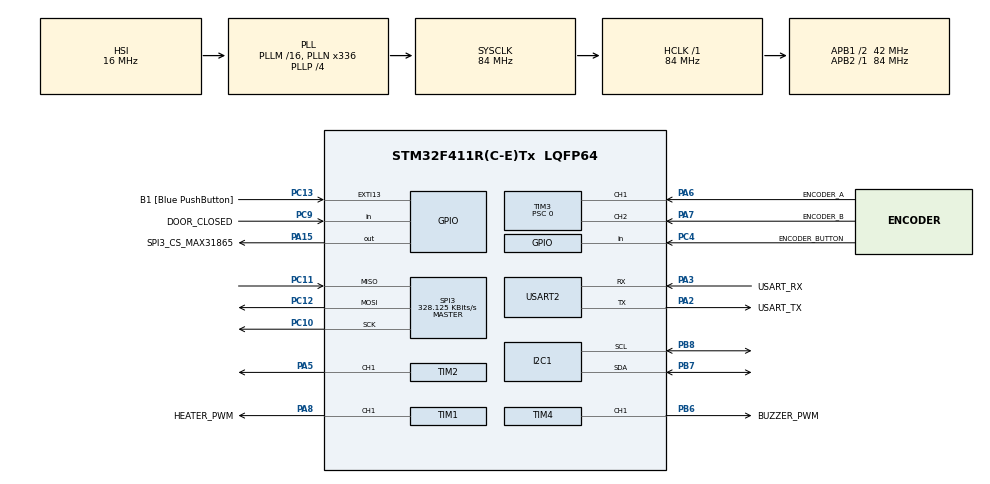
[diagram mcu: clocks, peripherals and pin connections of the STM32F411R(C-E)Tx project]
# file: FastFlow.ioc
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I2C1.I2C_Mode=I2C_Standard
Mcu.Family=STM32F4
Mcu.Name=STM32F411R(C-E)Tx
Mcu.Package=LQFP64
NVIC.PriorityGroup=NVIC_PRIORITYGROUP_0
PA13.GPIO_Label=TMS
PA13.Mode=Serial_Wire
PA13.Signal=SYS_JTMS-SWDIO
PA14.GPIO_Label=TCK
PA14.Mode=Serial_Wire
PA14.Signal=SYS_JTCK-SWCLK
PA15.GPIO_Label=SPI3_CS_MAX31865
PA15.Signal=GPIO_Output
PA2.GPIO_Label=USART_TX
PA2.Mode=Asynchronous
PA2.Signal=USART2_TX
PA3.GPIO_Label=USART_RX
PA3.Mode=Asynchronous
PA3.Signal=USART2_RX
PA5.Signal=S_TIM2_CH1_ETR
PA6.GPIO_Label=ENCODER_A
PA6.Signal=S_TIM3_CH1
PA7.GPIO_Label=ENCODER_B
PA7.Signal=S_TIM3_CH2
PA8.GPIO_Label=HEATER_PWM
PA8.Signal=S_TIM1_CH1
PB3.GPIO_Label=SWO
PB3.Signal=SYS_JTDO-SWO
PB6.GPIO_Label=BUZZER_PWM
PB6.Signal=S_TIM4_CH1
PB7.Mode=I2C
PB7.Signal=I2C1_SDA
PB8.Mode=I2C
PB8.Signal=I2C1_SCL
PC10.Mode=Full_Duplex_Master
PC10.Signal=SPI3_SCK
PC11.Mode=Full_Duplex_Master
PC11.Signal=SPI3_MISO
PC12.Mode=Full_Duplex_Master
PC12.Signal=SPI3_MOSI
PC13-ANTI_TAMP.GPIO_Label=B1 [Blue PushButton]
PC13-ANTI_TAMP.GPIO_ModeDefaultEXTI=GPIO_MODE_IT_FALLING
PC13-ANTI_TAMP.Signal=GPXTI13
PC14-OSC32_IN.Mode=LSE-External-Oscillator
PC14-OSC32_IN.Signal=RCC_OSC32_IN
PC15-OSC32_OUT.Mode=LSE-External-Oscillator
PC15-OSC32_OUT.Signal=RCC_OSC32_OUT
PC4.GPIO_Label=ENCODER_BUTTON
PC4.Signal=GPIO_Input
PC9.GPIO_Label=DOOR_CLOSED
PC9.Signal=GPIO_Input
PH0\ -\ OSC_IN.Mode=HSE-External-Clock-Source
PH0\ -\ OSC_IN.Signal=RCC_OSC_IN
PH1\ -\ OSC_OUT.Mode=HSE-External-Clock-Source
PH1\ -\ OSC_OUT.Signal=RCC_OSC_OUT
ProjectManager.HeapSize=0x200
ProjectManager.StackSize=0x400
ProjectManager.TargetToolchain=STM32CubeIDE
RCC.48MHZClocksFreq_Value=84000000
RCC.AHBFreq_Value=84000000
RCC.APB1CLKDivider=RCC_HCLK_DIV2
RCC.APB1Freq_Value=42000000
RCC.APB1TimFreq_Value=84000000
RCC.APB2Freq_Value=84000000
RCC.APB2TimFreq_Value=84000000
RCC.CortexFreq_Value=84000000
RCC.FLatency-AdvancedSettings=FLASH_LATENCY_2
RCC.HCLKFreq_Value=84000000
RCC.HSE_VALUE=8000000
RCC.HSI_VALUE=16000000
RCC.PLLN=336
RCC.PLLP=RCC_PLLP_DIV4
RCC.SYSCLKFreq_VALUE=84000000
RCC.SYSCLKSource=RCC_SYSCLKSOURCE_PLLCLK
RCC.VCOOutputFreq_Value=336000000
SH.S_TIM1_CH1.0=TIM1_CH1,Output Compare1 CH1
SH.S_TIM2_CH1_ETR.0=TIM2_CH1,PWM Generation1 CH1
SH.S_TIM3_CH1.0=TIM3_CH1,Encoder_Interface
SH.S_TIM3_CH2.0=TIM3_CH2,Encoder_Interface
SH.S_TIM4_CH1.0=TIM4_CH1,Output Compare1 CH1
SPI3.BaudRatePrescaler=SPI_BAUDRATEPRESCALER_128
SPI3.CLKPhase=SPI_PHASE_1EDGE
SPI3.CalculateBaudRate=328.125 KBits/s
SPI3.Direction=SPI_DIRECTION_2LINES
SPI3.Mode=SPI_MODE_MASTER
SPI3.VirtualType=VM_MASTER
TIM1.Channel-Output\ Compare1\ CH1=TIM_CHANNEL_1
TIM2.AutoReloadPreload=TIM_AUTORELOAD_PRELOAD_ENABLE
TIM2.Channel-PWM\ Generation1\ CH1=TIM_CHANNEL_1
TIM2.ClockDivision=TIM_CLOCKDIVISION_DIV1
TIM2.Period=0xFFFF
TIM2.Prescaler=0x0A04
TIM2.Pulse-PWM\ Generation1\ CH1=0x0FFF
TIM3.EncoderMode=TIM_ENCODERMODE_TI12
TIM3.IC1Filter=15
TIM3.IC1Prescaler=TIM_ICPSC_DIV1
TIM3.IC2Filter=15
TIM3.IC2Prescaler=TIM_ICPSC_DIV1
TIM3.Prescaler=0
TIM4.Channel-Output\ Compare1\ CH1=TIM_CHANNEL_1
TIM4.ClockDivision=TIM_CLOCKDIVISION_DIV4
TIM4.Period=0xFFFF
TIM4.Prescaler=20000
TIM4.Pulse-Output\ Compare1\ CH1=0x7FFF
USART2.VirtualMode=VM_ASYNC
VP_TIM2_VS_ClockSourceINT.Mode=Internal
VP_TIM4_VS_ClockSourceINT.Mode=Internal
board=NUCLEO-F411RE

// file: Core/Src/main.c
/* USER CODE BEGIN Header */
/**
  ******************************************************************************
  * @file           : main.c
  * @brief          : Main program body
  ******************************************************************************
  * @attention
  *
  * Copyright (c) 2024 STMicroelectronics.
  * All rights reserved.
  *
  * This software is licensed under terms that can be found in the LICENSE file
  * in the root directory of this software component.
  * If no LICENSE file comes with this software, it is provided AS-IS.
  *
  ******************************************************************************
  */
/* USER CODE END Header */
#include "main.h"
#include "i2c.h"
#include "spi.h"
#include "tim.h"
#include "usart.h"
#include "gpio.h"

/* USER CODE BEGIN Includes */

#include "fastFlow.h"
/* USER CODE END Includes */

void SystemClock_Config(void);

int main(void)
{

  /* MCU Configuration--------------------------------------------------------*/

  /* Reset of all peripherals, Initializes the Flash interface and the Systick. */
  HAL_Init();

  /* Configure the system clock */
  SystemClock_Config();

  /* Initialize all configured peripherals */
  MX_GPIO_Init();
  MX_USART2_UART_Init();
  MX_SPI3_Init();
  MX_TIM1_Init();
  MX_TIM3_Init();
  MX_TIM4_Init();
  MX_TIM2_Init();
  MX_I2C1_Init();
  /* USER CODE BEGIN 2 */
  fastFlow_init();
  fastFlow_run();

  /* USER CODE END 2 */

  /* Infinite loop */
  while (1)
  {

  }
}

void SystemClock_Config(void)
{
  RCC_OscInitTypeDef RCC_OscInitStruct = {0};
  RCC_ClkInitTypeDef RCC_ClkInitStruct = {0};

  /** Configure the main internal regulator output voltage
  */
  __HAL_RCC_PWR_CLK_ENABLE();
  __HAL_PWR_VOLTAGESCALING_CONFIG(PWR_REGULATOR_VOLTAGE_SCALE1);

  /** Initializes the RCC Oscillators according to the specified parameters
  * in the RCC_OscInitTypeDef structure.
  */
  RCC_OscInitStruct.OscillatorType = RCC_OSCILLATORTYPE_HSI;
  RCC_OscInitStruct.HSIState = RCC_HSI_ON;
  RCC_OscInitStruct.HSICalibrationValue = RCC_HSICALIBRATION_DEFAULT;
  RCC_OscInitStruct.PLL.PLLState = RCC_PLL_ON;
  RCC_OscInitStruct.PLL.PLLSource = RCC_PLLSOURCE_HSI;
  RCC_OscInitStruct.PLL.PLLM = 16;
  RCC_OscInitStruct.PLL.PLLN = 336;
  RCC_OscInitStruct.PLL.PLLP = RCC_PLLP_DIV4;
  RCC_OscInitStruct.PLL.PLLQ = 4;
  if (HAL_RCC_OscConfig(&RCC_OscInitStruct) != HAL_OK)
  {
    Error_Handler();
  }

  /** Initializes the CPU, AHB and APB buses clocks
  */
  RCC_ClkInitStruct.ClockType = RCC_CLOCKTYPE_HCLK|RCC_CLOCKTYPE_SYSCLK
                              |RCC_CLOCKTYPE_PCLK1|RCC_CLOCKTYPE_PCLK2;
  RCC_ClkInitStruct.SYSCLKSource = RCC_SYSCLKSOURCE_PLLCLK;
  RCC_ClkInitStruct.AHBCLKDivider = RCC_SYSCLK_DIV1;
  RCC_ClkInitStruct.APB1CLKDivider = RCC_HCLK_DIV2;
  RCC_ClkInitStruct.APB2CLKDivider = RCC_HCLK_DIV1;

  if (HAL_RCC_ClockConfig(&RCC_ClkInitStruct, FLASH_LATENCY_2) != HAL_OK)
  {
    Error_Handler();
  }
}

void Error_Handler(void)
{
  __disable_irq();
  while (1)
  {
  }
}
